# apollo1 register map
Vendor: Ambiq Micro; Series: Apollo; File version: 1.0
CPU: CM4 r1p0, little endian, MPU, FPU, 3 interrupt priority bits
Registers are 32-bit, read-write, reset 0x0 unless marked. A register's access mark holds for its fields unless they carry their own. Offsets are from the block's base; [hi:lo] are bit positions; {n}, {i} and the like mark numbered series; 'fields as' and 'values as' point back to an identical list.

## GPIO — General Purpose IO
Base 0x40010000
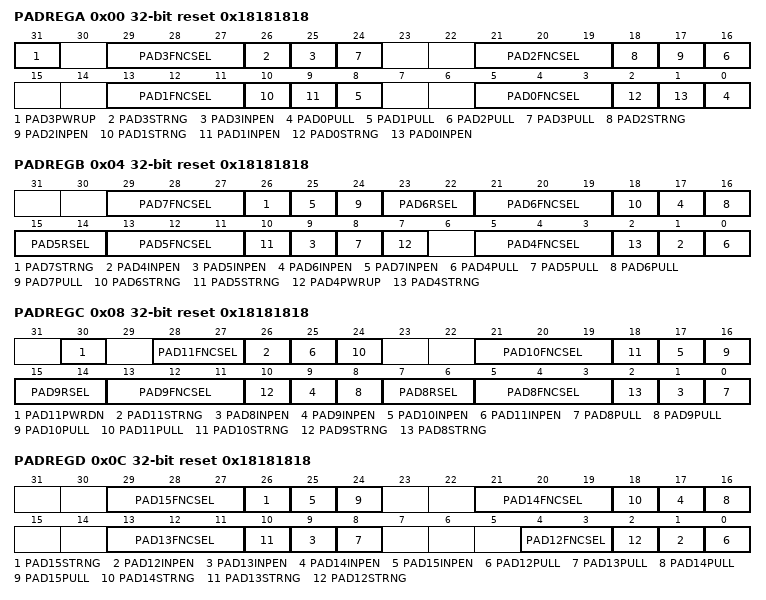
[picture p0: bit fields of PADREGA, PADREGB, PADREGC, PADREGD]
0x00 PADREGA reset 0x18181818 — Pad Configuration Register A
  [31] PAD3PWRUP — Pad 3 upper power switch enable
    0=DIS (Power switch disabled value.); 1=EN (Power switch enabled value.)
  [29:27] PAD3FNCSEL — Pad 3 function select
    0=TRIG0 (Configure as the ADC Trigger 0 signal value.); 1=SLnCE (Configure as the IOSLAVE SPI nCE signal value.); 2=M1nCE4 (Configure as the SPI channel 4 nCE signal from IOMSTR1 value.); 3=GPIO3 (Configure as GPIO3 value.); 4=M0nCE (Configure as the IOSLAVE SPI nCE loopback signal from IOMSTR0 value.); 5=M1nCE (Configure as the IOSLAVE SPI nCE loopback signal from IOMSTR1 value.); 6=DIS (Pad disabled value.)
  [26] PAD3STRNG — Pad 3 drive strength.
    0=LOW (Low drive strength value.); 1=HIGH (High drive strength value.)
  [25] PAD3INPEN — Pad 3 input enable.
    0=DIS (Pad input disabled value.); 1=EN (Pad input enabled value.)
  [8n] PAD{n}PULL (n=0..3) — Pad {n} pullup enable
    0=DIS (Pullup disabled value.); 1=EN (Pullup enabled value.)
  [21:19] PAD2FNCSEL — Pad 2 function select
    0=SLWIR3 (Configure as the IOSLAVE SPI 3-wire MOSI/MISO signal value.); 1=SLMOSI (Configure as the IOSLAVE SPI MOSI signal value.); 2=CLKOUT (Configure as the CLKOUT signal value.); 3=GPIO2 (Configure as GPIO2 value.); 4=M0MOSI (Configure as the IOSLAVE SPI MOSI loopback signal from IOMSTR0 value.); 5=M1MOSI (Configure as the IOSLAVE SPI MOSI loopback signal from IOMSTR1 value.); 6=M0WIR3 (Configure as the IOSLAVE SPI 3-wire MOSI/MISO loopback signal from IOMSTR0 value.); 7=M1WIR3 (Configure as the IOSLAVE SPI 3-wire MOSI/MISO loopback signal from IOMSTR1 value.)
  [18] PAD2STRNG — Pad 2 drive strength
    values as PAD3STRNG
  [17] PAD2INPEN — Pad 2 input enable
    values as PAD3INPEN
  [13:11] PAD1FNCSEL — Pad 1 function select
    0=SLSDA (Configure as the IOSLAVE I2C SDA signal value.); 1=SLMISO (Configure as the IOSLAVE SPI MISO signal value.); 2=UARTRX (Configure as the UART RX signal value.); 3=GPIO1 (Configure as GPIO1 value.); 4=M0MISO (Configure as the IOSLAVE SPI MISO loopback signal from IOMSTR0 value.); 5=M1MISO (Configure as the IOSLAVE SPI MISO loopback signal from IOMSTR1 value.); 6=M0SDA (Configure as the IOSLAVE I2C SDA loopback signal from IOMSTR0 value.); 7=M1SDA (Configure as the IOSLAVE I2C SDA loopback signal from IOMSTR1 value.)
  [10] PAD1STRNG — Pad 1 drive strength
    values as PAD3STRNG
  [9] PAD1INPEN — Pad 1 input enable
    values as PAD3INPEN
  [5:3] PAD0FNCSEL — Pad 0 function select
    0=SLSCL (Configure as the IOSLAVE I2C SCL signal value.); 1=SLSCK (Configure as the IOSLAVE SPI SCK signal value.); 2=UARTTX (Configure as the UART TX signal value.); 3=GPIO0 (Configure as GPIO0 value.); 4=M0SCK (Configure as the IOSLAVE SPI SCK loopback signal from IOMSTR0 value.); 5=M1SCK (Configure as the IOSLAVE SPI SCK loopback signal from IOMSTR1 value.); 6=M0SCL (Configure as the IOSLAVE I2C SCL loopback signal from IOMSTR0 value.); 7=M1SCL (Configure as the IOSLAVE I2C SCL loopback signal from IOMSTR1 value.)
  [2] PAD0STRNG — Pad 0 drive strength
    values as PAD3STRNG
  [1] PAD0INPEN — Pad 0 input enable
    values as PAD3INPEN
0x04 PADREGB reset 0x18181818 — Pad Configuration Register B
  [29:27] PAD7FNCSEL — Pad 7 function select
    0=M0WIR3 (Configure as the IOMSTR0 SPI 3-wire MOSI/MISO signal value.); 1=M0MOSI (Configure as the IOMSTR0 SPI MOSI signal value.); 2=CLKOUT (Configure as the CLKOUT signal value.); 3=GPIO7 (Configure as GPIO7 value.); 6=SLWIR3 (Configure as the IOMSTR0 SPI 3-wire MOSI/MISO loopback signal from IOSLAVE value.); 7=DIS (Pad disabled value.)
  [26] PAD7STRNG — Pad 7 drive strentgh
    values as PADREGA.PAD3STRNG
  [8n-31] PAD{n}INPEN (n=4..7) — Pad {n} input enable
    values as PADREGA.PAD3INPEN
  [8n-32] PAD{n}PULL (n=4..7) — Pad {n} pullup enable
    0=DIS (Pullup disabled value.); 1=EN (Pullup enabled value.)
  [23:22] PAD6RSEL — Pad 6 pullup resistor selection.
    0=PULL1_5K (Pullup is ~1.5 KOhms value.); 1=PULL6K (Pullup is ~6 KOhms value.); 2=PULL12K (Pullup is ~12 KOhms value.); 3=PULL24K (Pullup is ~24 KOhms value.)
  [21:19] PAD6FNCSEL — Pad 6 function select
    0=M0SDA (Configure as the IOMSTR0 I2C SDA signal value.); 1=M0MISO (Configure as the IOMSTR0 SPI MISO signal value.); 2=UACTS (Configure as the UART CTS signal value.); 3=GPIO6 (Configure as GPIO6 value.); 4=SLMISO (Configure as the IOMSTR0 SPI MISO loopback signal from IOSLAVE value.); 6=SLSDA (Configure as the IOMSTR0 I2C SDA loopback signal from IOSLAVE value.); 7=DIS (Pad disabled value.)
  [18] PAD6STRNG — Pad 6 drive strength
    values as PADREGA.PAD3STRNG
  [15:14] PAD5RSEL — Pad 5 pullup resistor selection.
    values as PAD6RSEL
  [13:11] PAD5FNCSEL — Pad 5 function select
    0=M0SCL (Configure as the IOMSTR0 I2C SCL signal value.); 1=M0SCK (Configure as the IOMSTR0 SPI SCK signal value.); 2=UARTS (Configure as the UART RTS signal value.); 3=GPIO5 (Configure as GPIO5 value.); 4=SLSCK (Configure as the IOMSTR0 SPI SCK loopback signal from IOSLAVE value.); 6=SLSCL (Configure as the IOMSTR0 I2C SCL loopback signal from IOSLAVE value.); 7=DIS (Pad disabled value.)
  [10] PAD5STRNG — Pad 5 drive strength
    values as PADREGA.PAD3STRNG
  [7] PAD4PWRUP — Pad 4 upper power switch enable
    values as PADREGA.PAD3PWRUP
  [5:3] PAD4FNCSEL — Pad 4 function select
    0=TRIG1 (Configure as the ADC Trigger 1 signal value.); 1=SLINT (Configure as the IOSLAVE interrupt out signal value.); 2=M0nCE5 (Configure as the SPI channel 5 nCE signal from IOMSTR0 value.); 3=GPIO4 (Configure as GPIO4 value.); 4=SLINTGP (Configure as the IOSLAVE interrupt loopback signal to GPIO4 value.); 5=SWO (Configure as the serial wire debug SWO signal value.); 6=CLKOUT (Configure as the CLKOUT signal value.); 7=DIS (Pad disabled value.)
  [2] PAD4STRNG — Pad 4 drive strength
    values as PADREGA.PAD3STRNG
0x08 PADREGC reset 0x18181818 — Pad Configuration Register C
  [30] PAD11PWRDN — Pad 11 lower power switch enable
    values as PADREGA.PAD3PWRUP
  [28:27] PAD11FNCSEL — Pad 11 function select
    0=ANATST (Configure as the analog test output signal value.); 1=M0nCE0 (Configure as the SPI channel 0 nCE signal from IOMSTR0 value.); 2=CLKOUT (Configure as the CLKOUT signal value.); 3=GPIO11 (Configure as GPIO11 value.)
  [26] PAD11STRNG — Pad 11 drive strentgh
    values as PADREGA.PAD3STRNG
  [8n-63] PAD{n}INPEN (n=8..11) — Pad {n} input enable
    values as PADREGA.PAD3INPEN
  [8n-64] PAD{n}PULL (n=8..11) — Pad {n} pullup enable
    0=DIS (Pullup disabled value.); 1=EN (Pullup enabled value.)
  [21:19] PAD10FNCSEL — Pad 10 function select
    0=M1WIR3 (Configure as the IOMSTR1 SPI 3-wire MOSI/MISO signal value.); 1=M1MOSI (Configure as the IOMSTR1 SPI MOSI signal value.); 2=M0nCE6 (Configure as the SPI channel 6 nCE signal from IOMSTR0 value.); 3=GPIO10 (Configure as GPIO10 value.); 5=EXTHFA (Configure as the external HFRC A clock signal value.); 6=DIS (Pad disabled value.); 7=SLWIR3 (Configure as the IOMSTR1 SPI 3-wire MOSI/MISO loopback signal from IOSLAVE value.)
  [18] PAD10STRNG — Pad 10 drive strength
    values as PADREGA.PAD3STRNG
  [15:14] PAD9RSEL — Pad 9 pullup resistor selection
    values as PADREGB.PAD6RSEL
  [13:11] PAD9FNCSEL — Pad 9 function select
    0=M1SDA (Configure as the IOMSTR1 I2C SDA signal value.); 1=M1MISO (Configure as the IOMSTR1 SPI MISO signal value.); 2=M0nCE5 (Configure as the SPI channel 5 nCE signal from IOMSTR0 value.); 3=GPIO9 (Configure as GPIO9 value.); 5=SLMISO (Configure as the IOMSTR1 SPI MISO loopback signal from IOSLAVE value.); 6=DIS (Pad disabled value.); 7=SLSDA (Configure as the IOMSTR1 I2C SDA loopback signal from IOSLAVE value.)
  [10] PAD9STRNG — Pad 9 drive strength
    values as PADREGA.PAD3STRNG
  [7:6] PAD8RSEL — Pad 8 pullup resistor selection.
    values as PADREGB.PAD6RSEL
  [5:3] PAD8FNCSEL — Pad 8 function select
    0=M1SCL (Configure as the IOMSTR1 I2C SCL signal value.); 1=M1SCK (Configure as the IOMSTR1 SPI SCK signal value.); 2=M0nCE4 (Configure as the SPI channel 4 nCE signal from IOMSTR0 value.); 3=GPIO8 (Configure as GPIO8 value.); 5=SLSCK (Configure as the IOMSTR1 SPI SCK loopback signal from IOSLAVE value.); 6=DIS (Pad disabled value.); 7=SLSCL (Configure as the IOMSTR1 I2C SCL loopback signal from IOSLAVE value.)
  [2] PAD8STRNG — Pad 8 drive strength
    values as PADREGA.PAD3STRNG
0x0C PADREGD reset 0x18181818 — Pad Configuration Register D
  [29:27] PAD15FNCSEL — Pad 15 function select
    0=ADC3 (Configure as the analog ADC input 3 value.); 1=M1nCE3 (Configure as the SPI channel 3 nCE signal from IOMSTR1 value.); 2=UARTRX (Configure as the UART RX signal value.); 3=GPIO15 (Configure as GPIO15 value.); 5=EXTXT (Configure as the external XT clock signal value.); 7=DIS (Pad disabled value.)
  [26] PAD15STRNG — Pad 15 drive strentgh
    values as PADREGA.PAD3STRNG
  [8n-95] PAD{n}INPEN (n=12..15) — Pad {n} input enable
    values as PADREGA.PAD3INPEN
  [8n-96] PAD{n}PULL (n=12..15) — Pad {n} pullup enable
    0=DIS (Pullup disabled value.); 1=EN (Pullup enabled value.)
  [21:19] PAD14FNCSEL — Pad 14 function select
    0=ADC2 (Configure as the analog ADC input 2 value.); 1=M1nCE2 (Configure as the SPI channel 2 nCE signal from IOMSTR1 value.); 2=UARTTX (Configure as the UART TX signal value.); 3=GPIO14 (Configure as GPIO14 value.); 5=EXTHFS (Configure as the external HFRC select signal value.); 7=DIS (Pad disabled value.)
  [18] PAD14STRNG — Pad 14 drive strength
    values as PADREGA.PAD3STRNG
  [13:11] PAD13FNCSEL — Pad 13 function select
    0=ADC1 (Configure as the analog ADC input 1 value.); 1=M1nCE1 (Configure as the SPI channel 1 nCE signal from IOMSTR1 value.); 2=TCTB0 (Configure as the input/output signal from CTIMER B0 value.); 3=GPIO13 (Configure as GPIO13 value.); 5=EXTHFA (Configure as the external HFRC B clock signal value.); 6=SWO (Configure as the serial wire debug SWO signal value.); 7=DIS (Pad disabled value.)
  [10] PAD13STRNG — Pad 13 drive strength
    values as PADREGA.PAD3STRNG
  [4:3] PAD12FNCSEL — Pad 12 function select
    0=ADC0 (Configure as the analog ADC input 0 value.); 1=M1nCE0 (Configure as the SPI channel 0 nCE signal from IOMSTR1 value.); 2=TCTA0 (Configure as the input/output signal from CTIMER A0 value.); 3=GPIO12 (Configure as GPIO12 value.)
  [2] PAD12STRNG — Pad 12 drive strength
    values as PADREGA.PAD3STRNG
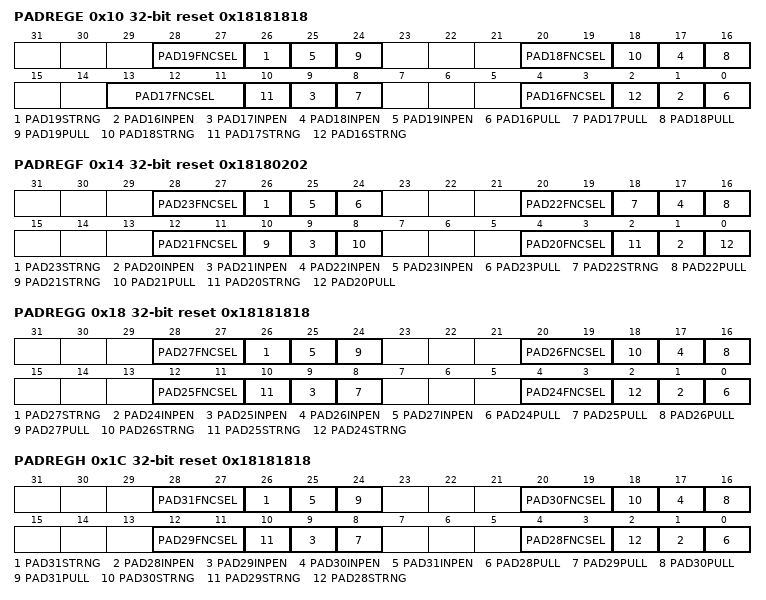
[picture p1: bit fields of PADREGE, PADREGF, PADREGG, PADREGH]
0x10 PADREGE reset 0x18181818 — Pad Configuration Register E
  [28:27] PAD19FNCSEL — Pad 19 function select
    0=CMPRF (Configure as the analog comparator reference signal value.); 1=M0nCE3 (Configure as the SPI channel 3 nCE signal from IOMSTR0 value.); 2=TCTB1 (Configure as the input/output signal from CTIMER B1 value.); 3=GPIO19 (Configure as GPIO19 value.)
  [26] PAD19STRNG — Pad 19 drive strentgh
    values as PADREGA.PAD3STRNG
  [8n-127] PAD{n}INPEN (n=16..19) — Pad {n} input enable
    values as PADREGA.PAD3INPEN
  [8n-128] PAD{n}PULL (n=16..19) — Pad {n} pullup enable
    0=DIS (Pullup disabled value.); 1=EN (Pullup enabled value.)
  [20:19] PAD18FNCSEL — Pad 18 function select
    0=CMPIN1 (Configure as the analog comparator input 1 signal value.); 1=M0nCE2 (Configure as the SPI channel 2 nCE signal from IOMSTR0 value.); 2=TCTA1 (Configure as the input/output signal from CTIMER A1 value.); 3=GPIO18 (Configure as GPIO18 value.)
  [18] PAD18STRNG — Pad 18 drive strength
    values as PADREGA.PAD3STRNG
  [13:11] PAD17FNCSEL — Pad 17 function select
    0=CMPIN0 (Configure as the analog comparator input 0 signal value.); 1=M0nCE1 (Configure as the SPI channel 1 nCE signal from IOMSTR0 value.); 2=TRIG3 (Configure as the ADC Trigger 3 signal value.); 3=GPIO17 (Configure as GPIO17 value.); 5=EXTLF (Configure as the external LFRC clock signal value.); 7=DIS (Pad disabled value.)
  [10] PAD17STRNG — Pad 17 drive strength
    values as PADREGA.PAD3STRNG
  [4:3] PAD16FNCSEL — Pad 16 function select
    0=ADCREF (Configure as the analog ADC reference input signal value.); 1=M0nCE4 (Configure as the SPI channel 4 nCE signal from IOMSTR0 value.); 2=TRIG2 (Configure as the ADC Trigger 2 signal value.); 3=GPIO16 (Configure as GPIO16 value.)
  [2] PAD16STRNG — Pad 16 drive strength
    values as PADREGA.PAD3STRNG
0x14 PADREGF reset 0x18180202 — Pad Configuration Register F
  [28:27] PAD23FNCSEL — Pad 23 function select
    0=UARTRX (Configure as the UART RX signal value.); 1=M0nCE0 (Configure as the SPI channel 0 nCE signal from IOMSTR0 value.); 2=TCTB3 (Configure as the input/output signal from CTIMER B3 value.); 3=GPIO23 (Configure as GPIO23 value.)
  [26] PAD23STRNG — Pad 23 drive strentgh
    values as PADREGA.PAD3STRNG
  [8n-159] PAD{n}INPEN (n=20..23) — Pad {n} input enable
    values as PADREGA.PAD3INPEN
  [24] PAD23PULL — Pad 23 pullup enable
    0=DIS (Pullup disabled value.); 1=EN (Pullup enabled value.)
  [20:19] PAD22FNCSEL — Pad 22 function select
    0=UARTTX (Configure as the UART TX signal value.); 1=M1nCE7 (Configure as the SPI channel 7 nCE signal from IOMSTR1 value.); 2=TCTA3 (Configure as the input/output signal from CTIMER A3 value.); 3=GPIO22 (Configure as GPIO22 value.)
  [18] PAD22STRNG — Pad 22 drive strength
    values as PADREGA.PAD3STRNG
  [16] PAD22PULL — Pad 22 pullup enable
    0=DIS (Pullup disabled value.); 1=EN (Pullup enabled value.)
  [12:11] PAD21FNCSEL — Pad 21 function select
    0=SWDIO (Configure as the serial wire debug data signal value.); 1=M1nCE6 (Configure as the SPI channel 6 nCE signal from IOMSTR1 value.); 2=TCTB2 (Configure as the input/output signal from CTIMER B2 value.); 3=GPIO21 (Configure as GPIO21 value.)
  [10] PAD21STRNG — Pad 21 drive strength
    values as PADREGA.PAD3STRNG
  [8] PAD21PULL — Pad 21 pullup enable
    0=DIS (Pullup disabled value.); 1=EN (Pullup enabled value.)
  [4:3] PAD20FNCSEL — Pad 20 function select
    0=SWDCK (Configure as the serial wire debug clock signal value.); 1=M1nCE5 (Configure as the SPI channel 5 nCE signal from IOMSTR1 value.); 2=TCTA2 (Configure as the input/output signal from CTIMER A2 value.); 3=GPIO20 (Configure as GPIO20 value.)
  [2] PAD20STRNG — Pad 20 drive strength
    values as PADREGA.PAD3STRNG
  [0] PAD20PULL — Pad 20 pulldown enable
    0=DIS (Pulldown disabled value.); 1=EN (Pulldown enabled value.)
0x18 PADREGG reset 0x18181818 — Pad Configuration Register G
  [28:27] PAD27FNCSEL — Pad 27 function select
    0=EXTHF (Configure as the external HFRC clock signal value.); 1=M1nCE4 (Configure as the SPI channel 4 nCE signal from IOMSTR1 value.); 2=TCTA1 (Configure as the input/output signal from CTIMER A1 value.); 3=GPIO27 (Configure as GPIO27 value.)
  [26] PAD27STRNG — Pad 27 drive strentgh
    values as PADREGA.PAD3STRNG
  [8n-191] PAD{n}INPEN (n=24..27) — Pad {n} input enable
    values as PADREGA.PAD3INPEN
  [8n-192] PAD{n}PULL (n=24..27) — Pad {n} pullup enable
    0=DIS (Pullup disabled value.); 1=EN (Pullup enabled value.)
  [20:19] PAD26FNCSEL — Pad 26 function select
    0=EXTLF (Configure as the external LFRC clock signal value.); 1=M0nCE3 (Configure as the SPI channel 3 nCE signal from IOMSTR0 value.); 2=TCTB0 (Configure as the input/output signal from CTIMER B0 value.); 3=GPIO26 (Configure as GPIO26 value.)
  [18] PAD26STRNG — Pad 26 drive strength
    values as PADREGA.PAD3STRNG
  [12:11] PAD25FNCSEL — Pad 25 function select
    0=EXTXT (Configure as the external XT clock signal value.); 1=M0nCE2 (Configure as the SPI channel 2 nCE signal from IOMSTR0 value.); 2=TCTA0 (Configure as the input/output signal from CTIMER A0 value.); 3=GPIO25 (Configure as GPIO25 value.)
  [10] PAD25STRNG — Pad 25 drive strength
    values as PADREGA.PAD3STRNG
  [4:3] PAD24FNCSEL — Pad 24 function select
    0=DIS (Pad disabled value.); 1=M0nCE1 (Configure as the SPI channel 1 nCE signal from IOMSTR0 value.); 2=CLKOUT (Configure as the CLKOUT signal value.); 3=GPIO24 (Configure as GPIO24 value.)
  [2] PAD24STRNG — Pad 24 drive strength
    values as PADREGA.PAD3STRNG
0x1C PADREGH reset 0x18181818 — Pad Configuration Register H
  [28:27] PAD31FNCSEL — Pad 31 function select
    0=ADC6 (Configure as the analog ADC input 6 signal value.); 1=M0nCE4 (Configure as the SPI channel 4 nCE signal from IOMSTR0 value.); 2=TCTA3 (Configure as the input/output signal from CTIMER A3 value.); 3=GPIO31 (Configure as GPIO31 value.)
  [26] PAD31STRNG — Pad 31 drive strentgh
    values as PADREGA.PAD3STRNG
  [8n-223] PAD{n}INPEN (n=28..31) — Pad {n} input enable
    values as PADREGA.PAD3INPEN
  [8n-224] PAD{n}PULL (n=28..31) — Pad {n} pullup enable
    0=DIS (Pullup disabled value.); 1=EN (Pullup enabled value.)
  [20:19] PAD30FNCSEL — Pad 30 function select
    0=ADC5 (Configure as the analog ADC input 5 signal value.); 1=M1nCE7 (Configure as the SPI channel 7 nCE signal from IOMSTR1 value.); 2=TCTB2 (Configure as the input/output signal from CTIMER B2 value.); 3=GPIO30 (Configure as GPIO30 value.)
  [18] PAD30STRNG — Pad 30 drive strength
    values as PADREGA.PAD3STRNG
  [12:11] PAD29FNCSEL — Pad 29 function select
    0=ADC4 (Configure as the analog ADC input 4 signal value.); 1=M1nCE6 (Configure as the SPI channel 6 nCE signal from IOMSTR1 value.); 2=TCTA2 (Configure as the input/output signal from CTIMER A2 value.); 3=GPIO29 (Configure as GPIO29 value.)
  [10] PAD29STRNG — Pad 29 drive strength
    values as PADREGA.PAD3STRNG
  [4:3] PAD28FNCSEL — Pad 28 function select
    0=DIS (Pad disabled value.); 1=M1nCE5 (Configure as the SPI channel 5 nCE signal from IOMSTR1 value.); 2=TCTB1 (Configure as the input/output signal from CTIMER B1 value.); 3=GPIO28 (Configure as GPIO28 value.)
  [2] PAD28STRNG — Pad 28 drive strength
    values as PADREGA.PAD3STRNG
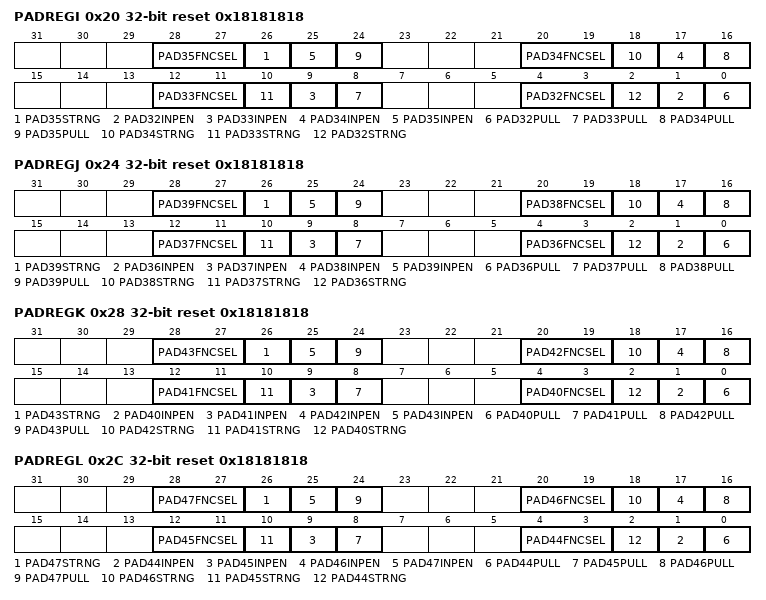
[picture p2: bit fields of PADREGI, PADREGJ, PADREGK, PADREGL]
0x20 PADREGI reset 0x18181818 — Pad Configuration Register I
  [28:27] PAD35FNCSEL — Pad 35 function select
    0=DIS (Pad disabled value.); 1=M1nCE0 (Configure as the SPI channel 0 nCE signal from IOMSTR1 value.); 2=UARTTX (Configure as the UART TX signal value.); 3=GPIO35 (Configure as GPIO35 value.)
  [26] PAD35STRNG — Pad 35 drive strentgh
    values as PADREGA.PAD3STRNG
  [8n-255] PAD{n}INPEN (n=32..35) — Pad {n} input enable
    values as PADREGA.PAD3INPEN
  [8n-256] PAD{n}PULL (n=32..35) — Pad {n} pullup enable
    0=DIS (Pullup disabled value.); 1=EN (Pullup enabled value.)
  [20:19] PAD34FNCSEL — Pad 34 function select
    0=CMPRF2 (Configure as the analog comparator reference 2 signal value.); 1=M0nCE7 (Configure as the SPI channel 7 nCE signal from IOMSTR0 value.); 2=DIS (Pad disabled value.); 3=GPIO34 (Configure as GPIO34 value.)
  [18] PAD34STRNG — Pad 34 drive strength
    values as PADREGA.PAD3STRNG
  [12:11] PAD33FNCSEL — Pad 33 function select
    0=CMPRF1 (Configure as the analog comparator reference 1 signal value.); 1=M0nCE6 (Configure as the SPI channel 6 nCE signal from IOMSTR0 value.); 2=DIS (Pad disabled value.); 3=GPIO33 (Configure as GPIO33 value.)
  [10] PAD33STRNG — Pad 33 drive strength
    values as PADREGA.PAD3STRNG
  [4:3] PAD32FNCSEL — Pad 32 function select
    0=ADC7 (Configure as the analog ADC input 7 signal value.); 1=M0nCE5 (Configure as the SPI channel 5 nCE signal from IOMSTR0 value.); 2=TCTB3 (Configure as the input/output signal from CTIMER B3 value.); 3=GPIO32 (Configure as GPIO32 value.)
  [2] PAD32STRNG — Pad 32 drive strength
    values as PADREGA.PAD3STRNG
0x24 PADREGJ reset 0x18181818 — Pad Configuration Register J
  [28:27] PAD39FNCSEL — Pad 39 function select
    0=TRIG2 (Configure as the ADC Trigger 2 signal value.); 1=UARTTX (Configure as the UART TX signal value.); 2=CLKOUT (Configure as the CLKOUT signal value.); 3=GPIO39 (Configure as GPIO39 value.)
  [26] PAD39STRNG — Pad 39 drive strentgh
    values as PADREGA.PAD3STRNG
  [8n-287] PAD{n}INPEN (n=36..39) — Pad {n} input enable
    values as PADREGA.PAD3INPEN
  [8n-288] PAD{n}PULL (n=36..39) — Pad {n} pullup enable
    0=DIS (Pullup disabled value.); 1=EN (Pullup enabled value.)
  [20:19] PAD38FNCSEL — Pad 38 function select
    0=TRIG1 (Configure as the ADC Trigger 1 signal value.); 1=M1nCE3 (Configure as the SPI channel 3 nCE signal from IOMSTR1 value.); 2=UACTS (Configure as the UART CTS signal value.); 3=GPIO38 (Configure as GPIO38 value.)
  [18] PAD38STRNG — Pad 38 drive strength
    values as PADREGA.PAD3STRNG
  [12:11] PAD37FNCSEL — Pad 37 function select
    0=TRIG0 (Configure as the ADC Trigger 0 signal value.); 1=M1nCE2 (Configure as the SPI channel 2 nCE signal from IOMSTR1 value.); 2=UARTS (Configure as the UART RTS signal value.); 3=GPIO37 (Configure as GPIO37 value.)
  [10] PAD37STRNG — Pad 37 drive strength
    values as PADREGA.PAD3STRNG
  [4:3] PAD36FNCSEL — Pad 36 function select
    0=DIS (Pad disabled value.); 1=M1nCE1 (Configure as the SPI channel 1 nCE signal from IOMSTR1 value.); 2=UARTRX (Configure as the UART RX signal value.); 3=GPIO36 (Configure as GPIO36 value.)
  [2] PAD36STRNG — Pad 36 drive strength
    values as PADREGA.PAD3STRNG
0x28 PADREGK reset 0x18181818 — Pad Configuration Register K
  [28:27] PAD43FNCSEL — Pad 43 function select
    0=TRIG6 (Configure as the ADC Trigger 6 signal value.); 1=M0nCE1 (Configure as the SPI channel 1 nCE signal from IOMSTR0 value.); 2=TCTB0 (Configure as the input/output signal from CTIMER B0 value.); 3=GPIO43 (Configure as GPIO43 value.)
  [26] PAD43STRNG — Pad 43 drive strentgh
    values as PADREGA.PAD3STRNG
  [8n-319] PAD{n}INPEN (n=40..43) — Pad {n} input enable
    values as PADREGA.PAD3INPEN
  [8n-320] PAD{n}PULL (n=40..43) — Pad {n} pullup enable
    0=DIS (Pullup disabled value.); 1=EN (Pullup enabled value.)
  [20:19] PAD42FNCSEL — Pad 42 function select
    0=TRIG5 (Configure as the ADC Trigger 5 signal value.); 1=M0nCE0 (Configure as the SPI channel 0 nCE signal from IOMSTR0 value.); 2=TCTA0 (Configure as the input/output signal from CTIMER A0 value.); 3=GPIO42 (Configure as GPIO42 value.)
  [18] PAD42STRNG — Pad 42 drive strength
    values as PADREGA.PAD3STRNG
  [12:11] PAD41FNCSEL — Pad 41 function select
    0=TRIG4 (Configure as the ADC Trigger 4 signal value.); 1=DIS (Pad disabled value.); 2=SWO (Configure as the serial wire debug SWO signal value.); 3=GPIO41 (Configure as GPIO41 value.)
  [10] PAD41STRNG — Pad 41 drive strength
    values as PADREGA.PAD3STRNG
  [4:3] PAD40FNCSEL — Pad 40 function select
    0=TRIG3 (Configure as the ADC Trigger 3 signal value.); 1=UARTRX (Configure as the UART RX signal value.); 2=DIS (Pad disabled value.); 3=GPIO40 (Configure as GPIO40 value.)
  [2] PAD40STRNG — Pad 40 drive strength
    values as PADREGA.PAD3STRNG
0x2C PADREGL reset 0x18181818 — Pad Configuration Register L
  [28:27] PAD47FNCSEL — Pad 47 function select
    0=DIS (Pad disabled value.); 1=M0nCE5 (Configure as the SPI channel 5 nCE signal from IOMSTR0 value.); 2=TCTB2 (Configure as the input/output signal from CTIMER B2 value.); 3=GPIO47 (Configure as GPIO47 value.)
  [26] PAD47STRNG — Pad 47 drive strentgh
    values as PADREGA.PAD3STRNG
  [8n-351] PAD{n}INPEN (n=44..47) — Pad {n} input enable
    values as PADREGA.PAD3INPEN
  [8n-352] PAD{n}PULL (n=44..47) — Pad {n} pullup enable
    0=DIS (Pullup disabled value.); 1=EN (Pullup enabled value.)
  [20:19] PAD46FNCSEL — Pad 46 function select
    0=DIS (Pad disabled value.); 1=M0nCE4 (Configure as the SPI channel 4 nCE signal from IOMSTR0 value.); 2=TCTA2 (Configure as the input/output signal from CTIMER A2 value.); 3=GPIO46 (Configure as GPIO46 value.)
  [18] PAD46STRNG — Pad 46 drive strength
    values as PADREGA.PAD3STRNG
  [12:11] PAD45FNCSEL — Pad 45 function select
    0=DIS (Pad disabled value.); 1=M0nCE3 (Configure as the SPI channel 3 nCE signal from IOMSTR0 value.); 2=TCTB1 (Configure as the input/output signal from CTIMER B1 value.); 3=GPIO45 (Configure as GPIO45 value.)
  [10] PAD45STRNG — Pad 45 drive strength
    values as PADREGA.PAD3STRNG
  [4:3] PAD44FNCSEL — Pad 44 function select
    0=TRIG7 (Configure as the ADC Trigger 7 signal value.); 1=M0nCE2 (Configure as the SPI channel 2 nCE signal from IOMSTR0 value.); 2=TCTA1 (Configure as the input/output signal from CTIMER A1 value.); 3=GPIO44 (Configure as GPIO44 value.)
  [2] PAD44STRNG — Pad 44 drive strength
    values as PADREGA.PAD3STRNG
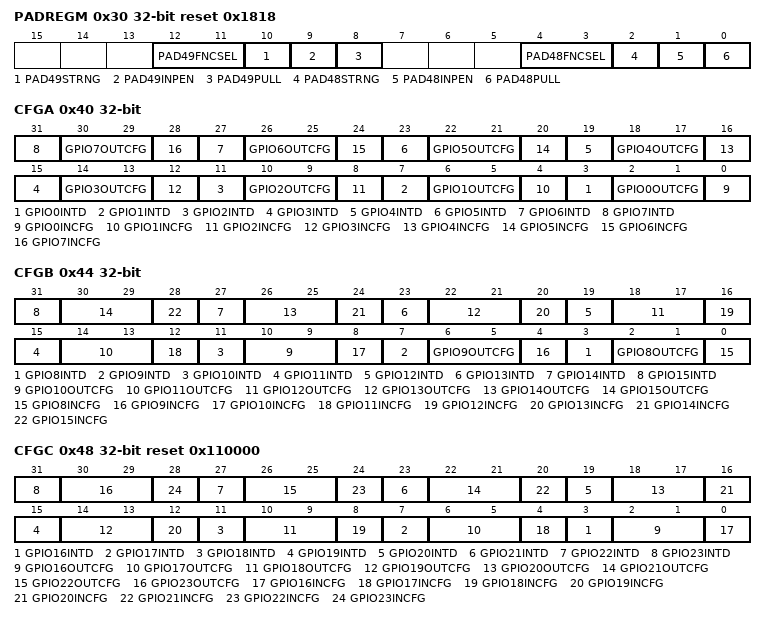
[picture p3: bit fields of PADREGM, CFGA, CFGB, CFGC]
0x30 PADREGM reset 0x1818 — Pad Configuration Register M
  [12:11] PAD49FNCSEL — Pad 49 function select
    0=DIS (Pad disabled value.); 1=M0nCE7 (Configure as the SPI channel 7 nCE signal from IOMSTR0 value.); 2=TCTB3 (Configure as the input/output signal from CTIMER B3 value.); 3=GPIO49 (Configure as GPIO49 value.)
  [10] PAD49STRNG — Pad 49 drive strength
    values as PADREGA.PAD3STRNG
  [9] PAD49INPEN — Pad 49 input enable
    values as PADREGA.PAD3INPEN
  [8] PAD49PULL — Pad 49 pullup enable
    0=DIS (Pullup disabled value.); 1=EN (Pullup enabled value.)
  [4:3] PAD48FNCSEL — Pad 48 function select
    0=DIS (Pad disabled value.); 1=M0nCE6 (Configure as the SPI channel 6 nCE signal from IOMSTR0 value.); 2=TCTA3 (Configure as the input/output signal from CTIMER A3 value.); 3=GPIO48 (Configure as GPIO48 value.)
  [2] PAD48STRNG — Pad 48 drive strength
    values as PADREGA.PAD3STRNG
  [1] PAD48INPEN — Pad 48 input enable
    values as PADREGA.PAD3INPEN
  [0] PAD48PULL — Pad 48 pullup enable
    0=DIS (Pullup disabled value.); 1=EN (Pullup enabled value.)
0x40 CFGA — GPIO Configuration Register A
  [4n+3] GPIO{n}INTD (n=0..7) — GPIO{n} interrupt direction.
    0=INTLH (Interrupt on low to high GPIO transition value.); 1=INTHL (Interrupt on high to low GPIO transition value.)
  [4n+2:4n+1] GPIO{n}OUTCFG (n=0..7) — GPIO{n} output configuration.
    0=DIS (Output disabled value.); 1=PUSHPULL (Output is push-pull value.); 2=OD (Output is open drain value.); 3=TS (Output is tri-state value.)
  [4n] GPIO{n}INCFG (n=0..7) — GPIO{n} input enable.
    0=READ (Read the GPIO pin data value.); 1=RDZERO (Readback will always be zero value.)
0x44 CFGB — GPIO Configuration Register B
  [4n-29] GPIO{n}INTD (n=8..15) — GPIO{n} interrupt direction.
    values as CFGA.GPIO0INTD
  [4n-30:4n-31] GPIO{n}OUTCFG (n=8..15) — GPIO{n} output configuration.
    values as CFGA.GPIO0OUTCFG
  [4n-32] GPIO{n}INCFG (n=8..15) — GPIO{n} input enable.
    values as CFGA.GPIO0INCFG
0x48 CFGC reset 0x110000 — GPIO Configuration Register C
  [4n-61] GPIO{n}INTD (n=16..23) — GPIO{n} interrupt direction.
    values as CFGA.GPIO0INTD
  [4n-62:4n-63] GPIO{n}OUTCFG (n=16..23) — GPIO{n} output configuration.
    values as CFGA.GPIO0OUTCFG
  [4n-64] GPIO{n}INCFG (n=16..23) — GPIO{n} input enable.
    values as CFGA.GPIO0INCFG
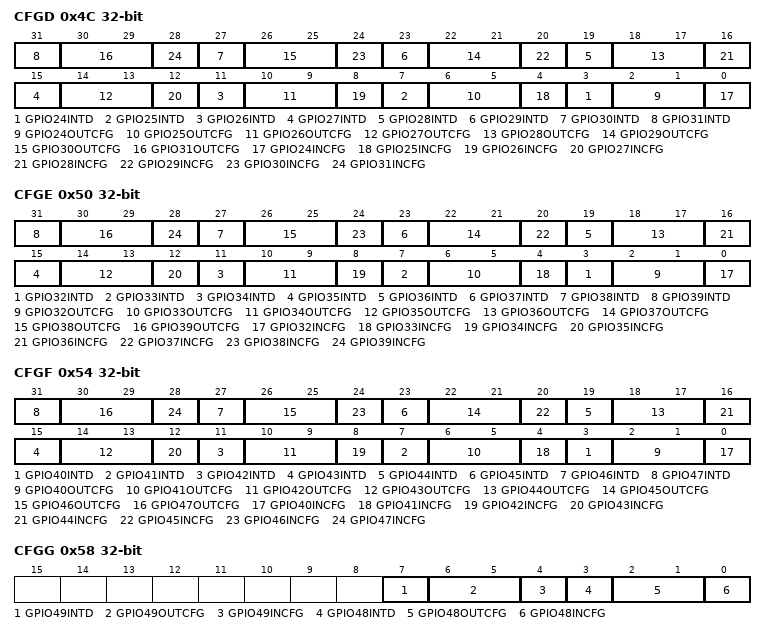
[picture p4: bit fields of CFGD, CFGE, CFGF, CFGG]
0x4C CFGD — GPIO Configuration Register D
  [4n-93] GPIO{n}INTD (n=24..31) — GPIO{n} interrupt direction.
    values as CFGA.GPIO0INTD
  [4n-94:4n-95] GPIO{n}OUTCFG (n=24..31) — GPIO{n} output configuration.
    values as CFGA.GPIO0OUTCFG
  [4n-96] GPIO{n}INCFG (n=24..31) — GPIO{n} input enable.
    values as CFGA.GPIO0INCFG
0x50 CFGE — GPIO Configuration Register E
  [4n-125] GPIO{n}INTD (n=32..39) — GPIO{n} interrupt direction.
    values as CFGA.GPIO0INTD
  [4n-126:4n-127] GPIO{n}OUTCFG (n=32..39) — GPIO{n} output configuration.
    values as CFGA.GPIO0OUTCFG
  [4n-128] GPIO{n}INCFG (n=32..39) — GPIO{n} input enable.
    values as CFGA.GPIO0INCFG
0x54 CFGF — GPIO Configuration Register F
  [4n-157] GPIO{n}INTD (n=40..47) — GPIO{n} interrupt direction.
    values as CFGA.GPIO0INTD
  [4n-158:4n-159] GPIO{n}OUTCFG (n=40..47) — GPIO{n} output configuration.
    values as CFGA.GPIO0OUTCFG
  [4n-160] GPIO{n}INCFG (n=40..47) — GPIO{n} input enable.
    values as CFGA.GPIO0INCFG
0x58 CFGG — GPIO Configuration Register G
  [7] GPIO49INTD — GPIO49 interrupt direction.
    values as CFGA.GPIO0INTD
  [6:5] GPIO49OUTCFG — GPIO49 output configuration.
    values as CFGA.GPIO0OUTCFG
  [4] GPIO49INCFG — GPIO49 input enable.
    values as CFGA.GPIO0INCFG
  [3] GPIO48INTD — GPIO48 interrupt direction.
    values as CFGA.GPIO0INTD
  [2:1] GPIO48OUTCFG — GPIO48 output configuration.
    values as CFGA.GPIO0OUTCFG
  [0] GPIO48INCFG — GPIO48 input enable.
    values as CFGA.GPIO0INCFG
0x60 PADKEY — Key Register for all pad configuration registers
  [31:0] PADKEY — Key register value.
    115=Key (Key value.)
0x80 RDA — GPIO Input Register A
  [31:0] RDA — GPIO31-0 read data.
0x84 RDB — GPIO Input Register B
  [17:0] RDB — GPIO49-32 read data.
0x88 WTA — GPIO Output Register A
  [31:0] WTA — GPIO31-0 write data.
0x8C WTB — GPIO Output Register B
  [17:0] WTB — GPIO49-32 write data.
0x90 WTSA — GPIO Output Register A Set
  [31:0] WTSA — Set the GPIO31-0 write data.
0x94 WTSB — GPIO Output Register B Set
  [17:0] WTSB — Set the GPIO49-32 write data.
0x98 WTCA — GPIO Output Register A Clear
  [31:0] WTCA — Clear the GPIO31-0 write data.
0x9C WTCB — GPIO Output Register B Clear
  [17:0] WTCB — Clear the GPIO49-32 write data.
0xA0 ENA — GPIO Enable Register A
  [31:0] ENA — GPIO31-0 output enables
0xA4 ENB — GPIO Enable Register B
  [17:0] ENB — GPIO49-32 output enables
0xA8 ENSA — GPIO Enable Register A Set
  [31:0] ENSA — Set the GPIO31-0 output enables
0xAC ENSB — GPIO Enable Register B Set
  [17:0] ENSB — Set the GPIO49-32 output enables
0xB4 ENCA — GPIO Enable Register A Clear
  [31:0] ENCA — Clear the GPIO31-0 output enables
0xB8 ENCB — GPIO Enable Register B Clear
  [17:0] ENCB — Clear the GPIO49-32 output enables
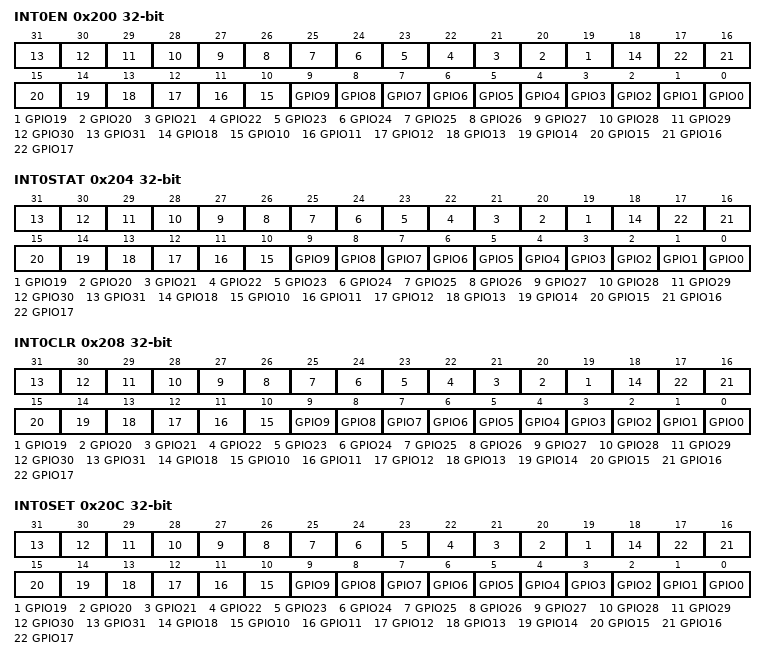
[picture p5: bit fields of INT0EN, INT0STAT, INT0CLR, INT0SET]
0x200 INT0EN — GPIO Interrupt Registers 31-0: Enable
  [n] GPIO{n} (n=19..31) — GPIO{n} interrupt.
  [18] GPIO18 — GPIO18interrupt.
  [n] GPIO{n} (n=0..17) — GPIO{n} interrupt.
0x204 INT0STAT — GPIO Interrupt Registers 31-0: Status
  fields as INT0EN
0x208 INT0CLR — GPIO Interrupt Registers 31-0: Clear
  fields as INT0EN
0x20C INT0SET — GPIO Interrupt Registers 31-0: Set
  fields as INT0EN
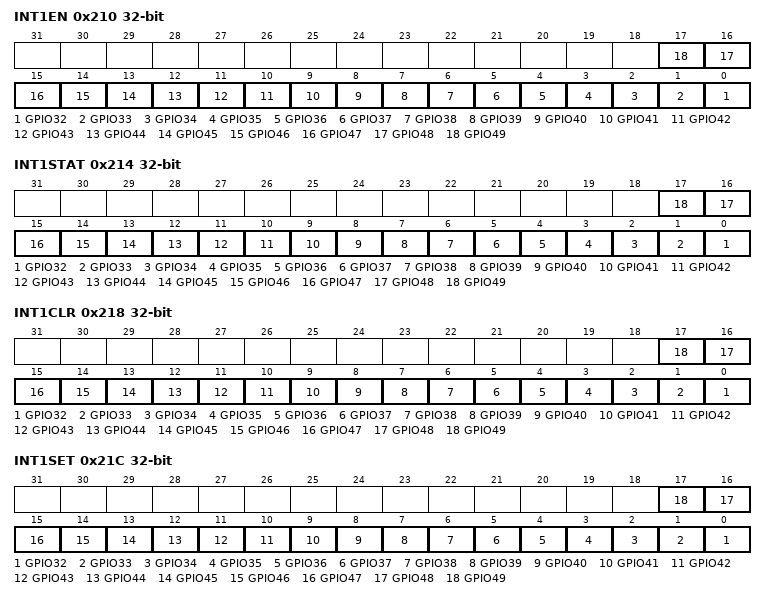
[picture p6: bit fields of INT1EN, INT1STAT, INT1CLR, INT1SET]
0x210 INT1EN — GPIO Interrupt Registers 49-32: Enable
  [n-32] GPIO{n} (n=32..49) — GPIO{n} interrupt.
0x214 INT1STAT — GPIO Interrupt Registers 49-32: Status
  [n-32] GPIO{n} (n=32..49) — GPIO{n} interrupt.
0x218 INT1CLR — GPIO Interrupt Registers 49-32: Clear
  [n-32] GPIO{n} (n=32..49) — GPIO{n} interrupt.
0x21C INT1SET — GPIO Interrupt Registers 49-32: Set
  [n-32] GPIO{n} (n=32..49) — GPIO{n} interrupt.
